# STM32F303 register map
File version: 1.7
Registers are 32-bit, read-write, reset 0x0 unless marked. A register's access mark holds for its fields unless they carry their own. Offsets are from the block's base; [hi:lo] are bit positions.

## DAC — Digital-to-analog converter
Base 0x40007400
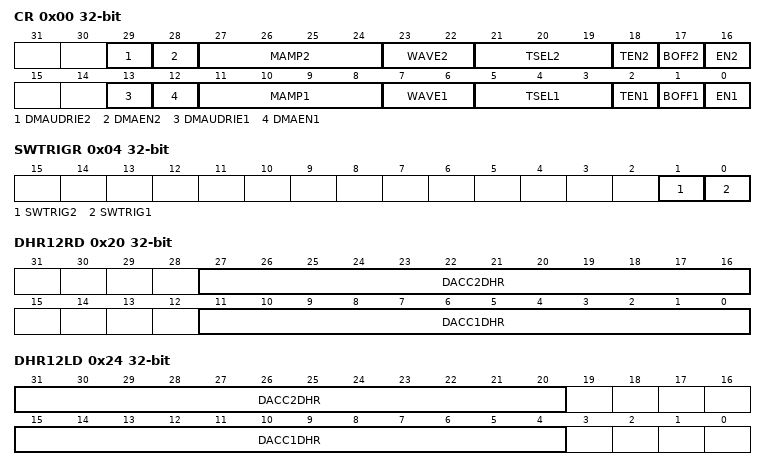
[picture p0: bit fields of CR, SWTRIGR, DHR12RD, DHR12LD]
0x00 CR — control register
  [29] DMAUDRIE2 — DAC channel2 DMA underrun interrupt enable
  [28] DMAEN2 — DAC channel2 DMA enable
  [27:24] MAMP2 — DAC channel2 mask/amplitude selector
  [23:22] WAVE2 — DAC channel2 noise/triangle wave generation enable
  [21:19] TSEL2 — DAC channel2 trigger selection
  [18] TEN2 — DAC channel2 trigger enable
  [17] BOFF2 — DAC channel2 output buffer disable
  [16] EN2 — DAC channel2 enable
  [13] DMAUDRIE1 — DAC channel1 DMA Underrun Interrupt enable
  [12] DMAEN1 — DAC channel1 DMA enable
  [11:8] MAMP1 — DAC channel1 mask/amplitude selector
  [7:6] WAVE1 — DAC channel1 noise/triangle wave generation enable
  [5:3] TSEL1 — DAC channel1 trigger selection
  [2] TEN1 — DAC channel1 trigger enable
  [1] BOFF1 — DAC channel1 output buffer disable
  [0] EN1 — DAC channel1 enable
0x04 SWTRIGR wo — software trigger register
  [1] SWTRIG2 — DAC channel2 software trigger
  [0] SWTRIG1 — DAC channel1 software trigger
0x08 DHR12R1 — channel1 12-bit right-aligned data holding register
  [11:0] DACC1DHR — DAC channel1 12-bit right-aligned data
0x0C DHR12L1 — channel1 12-bit left aligned data holding register
  [15:4] DACC1DHR — DAC channel1 12-bit left-aligned data
0x10 DHR8R1 — channel1 8-bit right aligned data holding register
  [7:0] DACC1DHR — DAC channel1 8-bit right-aligned data
0x14 DHR12R2 — channel2 12-bit right aligned data holding register
  [11:0] DACC2DHR — DAC channel2 12-bit right-aligned data
0x18 DHR12L2 — channel2 12-bit left aligned data holding register
  [15:4] DACC2DHR — DAC channel2 12-bit left-aligned data
0x1C DHR8R2 — channel2 8-bit right-aligned data holding register
  [7:0] DACC2DHR — DAC channel2 8-bit right-aligned data
0x20 DHR12RD — Dual DAC 12-bit right-aligned data holding register
  [27:16] DACC2DHR — DAC channel2 12-bit right-aligned data
  [11:0] DACC1DHR — DAC channel1 12-bit right-aligned data
0x24 DHR12LD — DUAL DAC 12-bit left aligned data holding register
  [31:20] DACC2DHR — DAC channel2 12-bit left-aligned data
  [15:4] DACC1DHR — DAC channel1 12-bit left-aligned data
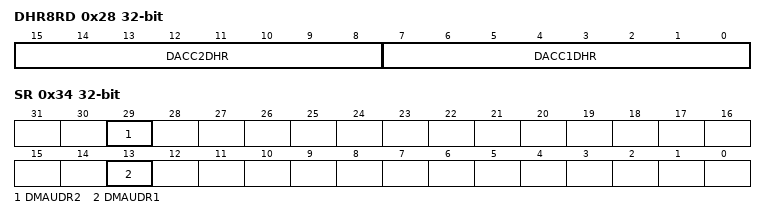
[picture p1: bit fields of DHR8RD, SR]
0x28 DHR8RD — DUAL DAC 8-bit right aligned data holding register
  [15:8] DACC2DHR — DAC channel2 8-bit right-aligned data
  [7:0] DACC1DHR — DAC channel1 8-bit right-aligned data
0x2C DOR1 ro — channel1 data output register
  [11:0] DACC1DOR — DAC channel1 data output
0x30 DOR2 ro — channel2 data output register
  [11:0] DACC2DOR — DAC channel2 data output
0x34 SR — status register
  [29] DMAUDR2 — DAC channel2 DMA underrun flag
  [13] DMAUDR1 — DAC channel1 DMA underrun flag

## TIM6 — Basic timers
Base 0x40001000
Same registers: TIM7 0x40001400
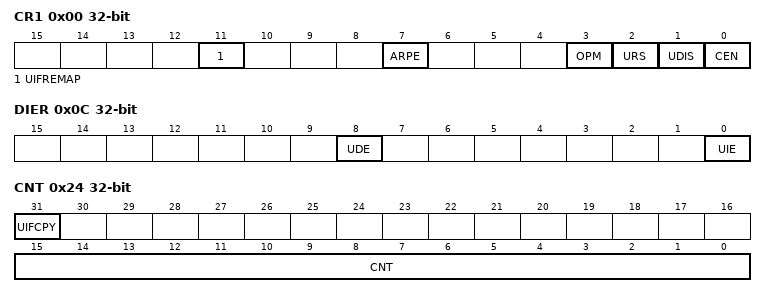
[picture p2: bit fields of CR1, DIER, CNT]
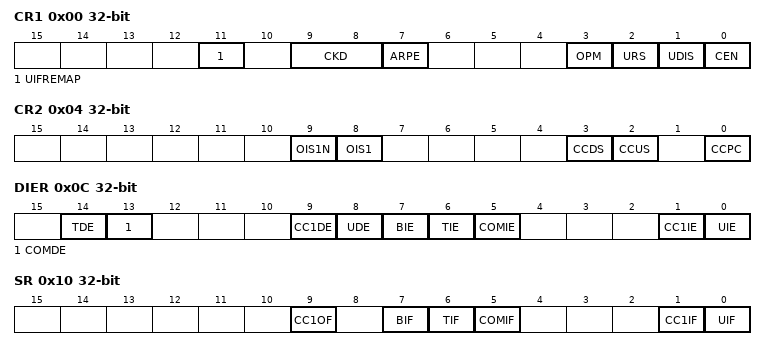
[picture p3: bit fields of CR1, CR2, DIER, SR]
0x00 CR1 — control register 1
  [11] UIFREMAP — UIF status bit remapping
  [7] ARPE — Auto-reload preload enable
  [3] OPM — One-pulse mode
  [2] URS — Update request source
  [1] UDIS — Update disable
  [0] CEN — Counter enable
0x04 CR2 — control register 2
  [6:4] MMS — Master mode selection
0x0C DIER — DMA/Interrupt enable register
  [8] UDE — Update DMA request enable
  [0] UIE — Update interrupt enable
0x10 SR — status register
  [0] UIF — Update interrupt flag
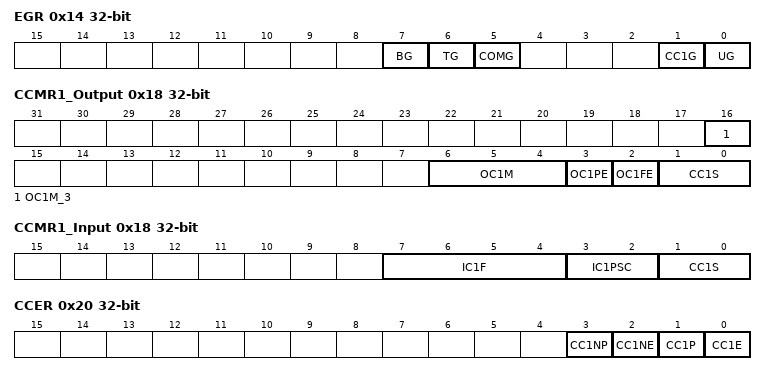
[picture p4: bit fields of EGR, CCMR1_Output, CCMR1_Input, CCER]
0x14 EGR wo — event generation register
  [0] UG — Update generation
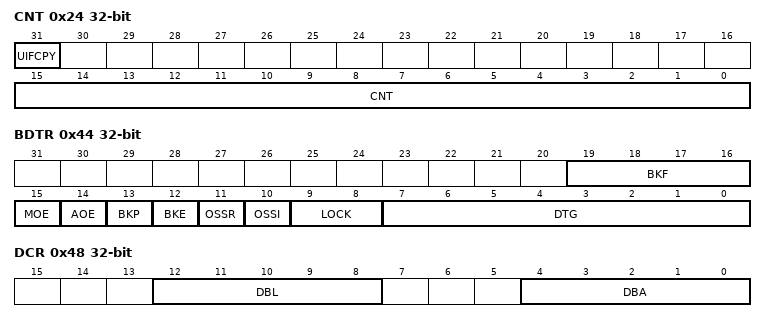
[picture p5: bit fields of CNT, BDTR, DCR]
0x24 CNT access per field — counter
  [31] UIFCPY ro — UIF Copy
  [15:0] CNT rw — Low counter value
0x28 PSC — prescaler
  [15:0] PSC — Prescaler value
0x2C ARR — auto-reload register
  [15:0] ARR — Low Auto-reload value

## TIM16 — General-purpose-timers
Base 0x40014400
0x00 CR1 — control register 1
  [11] UIFREMAP — UIF status bit remapping
  [9:8] CKD — Clock division
  [7] ARPE — Auto-reload preload enable
  [3] OPM — One-pulse mode
  [2] URS — Update request source
  [1] UDIS — Update disable
  [0] CEN — Counter enable
0x04 CR2 — control register 2
  [9] OIS1N — Output Idle state 1
  [8] OIS1 — Output Idle state 1
  [3] CCDS — Capture/compare DMA selection
  [2] CCUS — Capture/compare control update selection
  [0] CCPC — Capture/compare preloaded control
0x0C DIER — DMA/Interrupt enable register
  [14] TDE — Trigger DMA request enable
  [13] COMDE — COM DMA request enable
  [9] CC1DE — Capture/Compare 1 DMA request enable
  [8] UDE — Update DMA request enable
  [7] BIE — Break interrupt enable
  [6] TIE — Trigger interrupt enable
  [5] COMIE — COM interrupt enable
  [1] CC1IE — Capture/Compare 1 interrupt enable
  [0] UIE — Update interrupt enable
0x10 SR — status register
  [9] CC1OF — Capture/Compare 1 overcapture flag
  [7] BIF — Break interrupt flag
  [6] TIF — Trigger interrupt flag
  [5] COMIF — COM interrupt flag
  [1] CC1IF — Capture/compare 1 interrupt flag
  [0] UIF — Update interrupt flag
0x14 EGR wo — event generation register
  [7] BG — Break generation
  [6] TG — Trigger generation
  [5] COMG — Capture/Compare control update generation
  [1] CC1G — Capture/compare 1 generation
  [0] UG — Update generation
0x18 CCMR1_Output — capture/compare mode register (output mode)
  [16] OC1M_3 — Output Compare 1 mode
  [6:4] OC1M — Output Compare 1 mode
  [3] OC1PE — Output Compare 1 preload enable
  [2] OC1FE — Output Compare 1 fast enable
  [1:0] CC1S — Capture/Compare 1 selection
0x18 CCMR1_Input (alternate view of CCMR1_Output) — capture/compare mode register 1 (input mode)
  [7:4] IC1F — Input capture 1 filter
  [3:2] IC1PSC — Input capture 1 prescaler
  [1:0] CC1S — Capture/Compare 1 selection
0x20 CCER — capture/compare enable register
  [3] CC1NP — Capture/Compare 1 output Polarity
  [2] CC1NE — Capture/Compare 1 complementary output enable
  [1] CC1P — Capture/Compare 1 output Polarity
  [0] CC1E — Capture/Compare 1 output enable
0x24 CNT access per field — counter
  [31] UIFCPY ro — UIF Copy
  [15:0] CNT rw — counter value
0x28 PSC — prescaler
  [15:0] PSC — Prescaler value
0x2C ARR — auto-reload register
  [15:0] ARR — Auto-reload value
0x30 RCR — repetition counter register
  [7:0] REP — Repetition counter value
0x34 CCR1 — capture/compare register 1
  [15:0] CCR1 — Capture/Compare 1 value
0x44 BDTR — break and dead-time register
  [19:16] BKF — Break filter
  [15] MOE — Main output enable
  [14] AOE — Automatic output enable
  [13] BKP — Break polarity
  [12] BKE — Break enable
  [11] OSSR — Off-state selection for Run mode
  [10] OSSI — Off-state selection for Idle mode
  [9:8] LOCK — Lock configuration
  [7:0] DTG — Dead-time generator setup
0x48 DCR — DMA control register
  [12:8] DBL — DMA burst length
  [4:0] DBA — DMA base address
0x4C DMAR — DMA address for full transfer
  [15:0] DMAB — DMA register for burst accesses
0x50 OR — option register

## TIM17 — General purpose timer
Base 0x40014800
Registers as TIM16, without OR.
